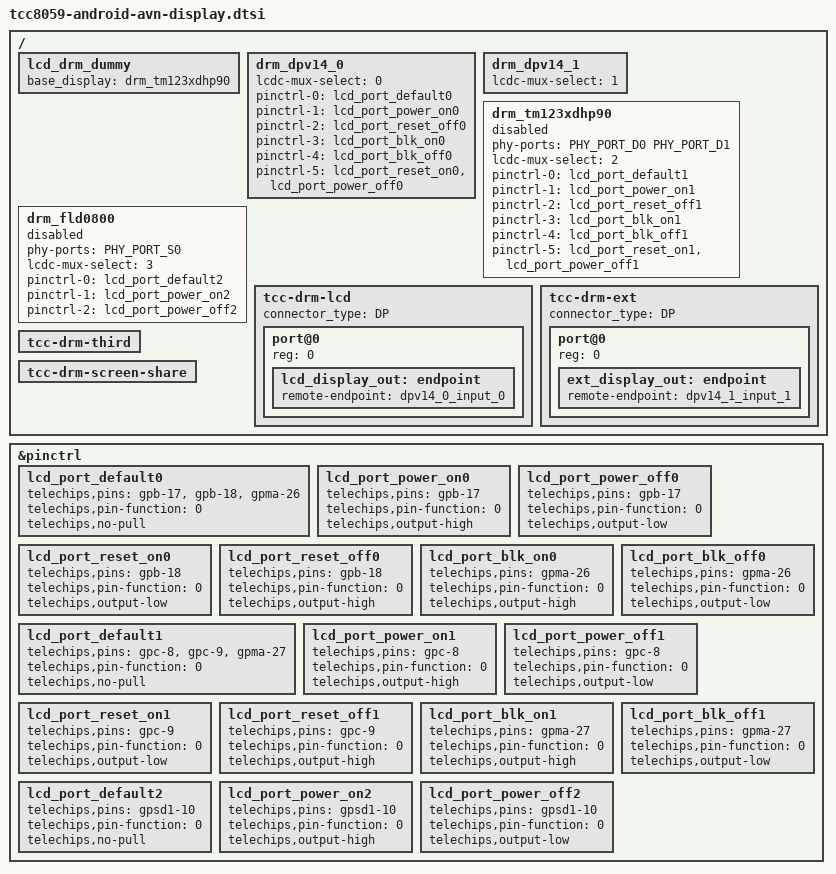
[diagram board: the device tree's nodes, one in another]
// SPDX-License-Identifier: (GPL-2.0-or-later OR MIT)
/*
 * Copyright (C) Telechips Inc.
 * Device tree for Telechips TCC8059 AVN board
 */

#include "tcc805x-display.dtsi"

/* LCD POWER PORT 1 */
&pinctrl {
	lcd_port_default0:lcd_port_default0 {
		telechips,pins = "gpb-17", "gpb-18", "gpma-26";
		telechips,pin-function = <0>;
		telechips,no-pull;
	};
	/* LVDS power on */
	lcd_port_power_on0:lcd_port_power_on0 {
		telechips,pins = "gpb-17";
		telechips,pin-function = <0>;
		telechips,output-high;
	};
	lcd_port_power_off0:lcd_port_power_off0 {
		telechips,pins = "gpb-17";
		telechips,pin-function = <0>;
		telechips,output-low;
	};
	lcd_port_reset_on0:lcd_port_reset_on0 {
		telechips,pins = "gpb-18";
		telechips,pin-function = <0>;
		telechips,output-low;
	};
	lcd_port_reset_off0:lcd_port_reset_off0 {
		telechips,pins = "gpb-18";
		telechips,pin-function = <0>;
		telechips,output-high;
	};
	lcd_port_blk_on0:lcd_port_blk_on0 {
		telechips,pins = "gpma-26";
		telechips,pin-function = <0>;
		telechips,output-high;
	};
	lcd_port_blk_off0:lcd_port_blk_off0 {
		telechips,pins = "gpma-26";
		telechips,pin-function = <0>;
		telechips,output-low;
	};
};

/* LCD POWER PORT 2 */
&pinctrl {
	lcd_port_default1:lcd_port_default1 {
		telechips,pins = "gpc-8", "gpc-9", "gpma-27";
		telechips,pin-function = <0>;
		telechips,no-pull;
	};
	/* LVDS power on */
	lcd_port_power_on1:lcd_port_power_on1 {
		telechips,pins = "gpc-8";
		telechips,pin-function = <0>;
		telechips,output-high;
	};
	lcd_port_power_off1:lcd_port_power_off1 {
		telechips,pins = "gpc-8";
		telechips,pin-function = <0>;
		telechips,output-low;
	};
	lcd_port_reset_on1:lcd_port_reset_on1 {
		telechips,pins = "gpc-9";
		telechips,pin-function = <0>;
		telechips,output-low;
	};
	lcd_port_reset_off1:lcd_port_reset_off1 {
		telechips,pins = "gpc-9";
		telechips,pin-function = <0>;
		telechips,output-high;
	};
	lcd_port_blk_on1:lcd_port_blk_on1 {
		telechips,pins = "gpma-27";
		telechips,pin-function = <0>;
		telechips,output-high;
	};
	lcd_port_blk_off1:lcd_port_blk_off1 {
		telechips,pins = "gpma-27";
		telechips,pin-function = <0>;
		telechips,output-low;
	};
};

/* LCD POWER PORT 3 */
&pinctrl {
	lcd_port_default2:lcd_port_default2 {
		telechips,pins = "gpsd1-10";
		telechips,pin-function = <0>;
		telechips,no-pull;
	};
	/* LVDS power on */
	lcd_port_power_on2:lcd_port_power_on2 {
		telechips,pins = "gpsd1-10";
		telechips,pin-function = <0>;
		telechips,output-high;
	};
	lcd_port_power_off2:lcd_port_power_off2 {
		telechips,pins = "gpsd1-10";
		telechips,pin-function = <0>;
		telechips,output-low;
	};
};


/ {
	/* Describe here after remove this statement if you have something to be override. */
	lcd_drm_dummy {
		status = "okay";
		base_display = <&drm_tm123xdhp90>;
	};

	drm_dpv14_0 {
		status = "okay";

		lcdc-mux-select = <0>;

		pinctrl-names = "default", "power_on", "reset_off", "blk_on", "blk_off", "power_off";
		pinctrl-0 = <&lcd_port_default0>;
		pinctrl-1 = <&lcd_port_power_on0>;
		pinctrl-2 = <&lcd_port_reset_off0>;
		pinctrl-3 = <&lcd_port_blk_on0>;
		pinctrl-4 = <&lcd_port_blk_off0>;
		pinctrl-5 = <&lcd_port_reset_on0 &lcd_port_power_off0>;
	};

	drm_dpv14_1 {
		status = "okay";

		lcdc-mux-select = <1>;
	};

	drm_tm123xdhp90 {
		status = "disabled";

		phy-ports = <PHY_PORT_D0 PHY_PORT_D1>;
		lcdc-mux-select = <2>;
		pinctrl-names = "default", "pwr_on_1", "pwr_on_2",
					"blk_on", "blk_off", "power_off";
                pinctrl-0 = <&lcd_port_default1>;
		pinctrl-1 = <&lcd_port_power_on1>;
		pinctrl-2 = <&lcd_port_reset_off1>;
		pinctrl-3 = <&lcd_port_blk_on1>;
		pinctrl-4 = <&lcd_port_blk_off1>;
		pinctrl-5 = <&lcd_port_reset_on1 &lcd_port_power_off1>;
	};

	drm_fld0800 {
		status = "disabled";

		phy-ports = <PHY_PORT_S0>;
		lcdc-mux-select = <3>;
		pinctrl-names = "default", "pwr_on_1", "power_off";
                pinctrl-0 = <&lcd_port_default2>;
		pinctrl-1 = <&lcd_port_power_on2>;
		pinctrl-2 = <&lcd_port_power_off2>;
	};

	tcc-drm-lcd {
		status = "okay";
		connector_type = "DP";
		port@0 {
			reg = <0>;
			lcd_display_out: endpoint {
				remote-endpoint = <&dpv14_0_input_0>;
			};
		};
	};

	tcc-drm-ext {
		status = "okay";
		connector_type = "DP";
		port@0 {
			reg = <0>;
			ext_display_out: endpoint {
				remote-endpoint = <&dpv14_1_input_1>;
			};
		};
	};

	tcc-drm-third {
		status = "okay";
	};

	tcc-drm-screen-share {
		status = "okay";
	};
};

